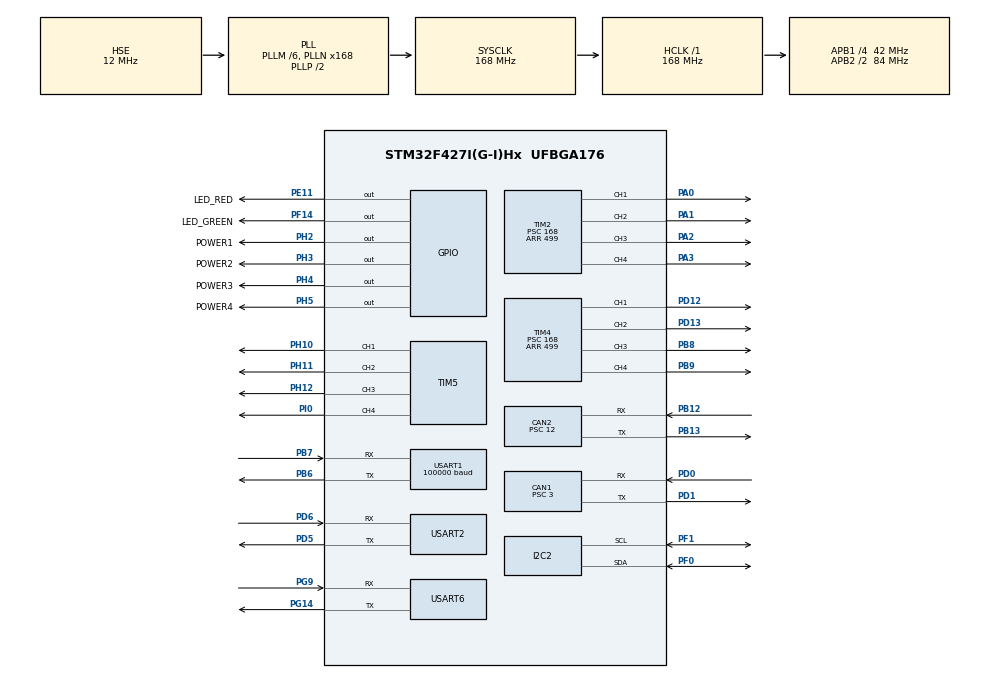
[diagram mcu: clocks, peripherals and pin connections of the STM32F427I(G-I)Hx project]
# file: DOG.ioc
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CAN1.BS1=CAN_BS1_10TQ
CAN1.BS2=CAN_BS2_3TQ
CAN1.CalculateBaudRate=1000000
CAN1.CalculateTimeBit=1000
CAN1.CalculateTimeQuantum=71.42857142857143
CAN1.Prescaler=3
CAN1.TXFP=DISABLE
CAN2.BS1=CAN_BS1_10TQ
CAN2.BS2=CAN_BS2_3TQ
CAN2.CalculateBaudRate=250000
CAN2.CalculateTimeBit=4000
CAN2.CalculateTimeQuantum=285.7142857142857
CAN2.Prescaler=12
CAN2.TXFP=DISABLE
Dma.Request0=USART1_RX
Dma.Request1=USART6_RX
Dma.USART1_RX.0.Direction=DMA_PERIPH_TO_MEMORY
Dma.USART1_RX.0.FIFOMode=DMA_FIFOMODE_DISABLE
Dma.USART1_RX.0.Instance=DMA2_Stream2
Dma.USART1_RX.0.MemDataAlignment=DMA_MDATAALIGN_BYTE
Dma.USART1_RX.0.MemInc=DMA_MINC_ENABLE
Dma.USART1_RX.0.Mode=DMA_CIRCULAR
Dma.USART1_RX.0.PeriphDataAlignment=DMA_PDATAALIGN_BYTE
Dma.USART1_RX.0.PeriphInc=DMA_PINC_DISABLE
Dma.USART1_RX.0.Priority=DMA_PRIORITY_LOW
Dma.USART6_RX.1.Direction=DMA_PERIPH_TO_MEMORY
Dma.USART6_RX.1.FIFOMode=DMA_FIFOMODE_DISABLE
Dma.USART6_RX.1.Instance=DMA2_Stream1
Dma.USART6_RX.1.MemDataAlignment=DMA_MDATAALIGN_BYTE
Dma.USART6_RX.1.MemInc=DMA_MINC_ENABLE
Dma.USART6_RX.1.Mode=DMA_NORMAL
Dma.USART6_RX.1.PeriphDataAlignment=DMA_PDATAALIGN_BYTE
Dma.USART6_RX.1.PeriphInc=DMA_PINC_DISABLE
Dma.USART6_RX.1.Priority=DMA_PRIORITY_LOW
FREERTOS.INCLUDE_eTaskGetState=1
FREERTOS.INCLUDE_pcTaskGetTaskName=1
FREERTOS.INCLUDE_uxTaskGetStackHighWaterMark=1
FREERTOS.INCLUDE_vTaskCleanUpResources=1
FREERTOS.INCLUDE_vTaskDelayUntil=1
FREERTOS.INCLUDE_xEventGroupSetBitFromISR=1
FREERTOS.INCLUDE_xQueueGetMutexHolder=1
FREERTOS.INCLUDE_xSemaphoreGetMutexHolder=1
FREERTOS.INCLUDE_xTaskAbortDelay=1
FREERTOS.INCLUDE_xTaskGetCurrentTaskHandle=1
FREERTOS.INCLUDE_xTaskGetHandle=1
FREERTOS.INCLUDE_xTimerPendFunctionCall=1
FREERTOS.Tasks01=defaultTask,0,128,StartDefaultTask,Default,NULL,Dynamic,NULL,NULL
FREERTOS.configTOTAL_HEAP_SIZE=24576
FREERTOS.configUSE_TIMERS=1
I2C2.I2C_Mode=I2C_Fast
Mcu.Family=STM32F4
Mcu.Name=STM32F427I(G-I)Hx
Mcu.Package=UFBGA176
NVIC.CAN1_RX0_IRQn=true\:5\:0\:false\:false\:true\:true\:true\:true\:true
NVIC.CAN2_RX0_IRQn=true\:5\:0\:false\:false\:true\:true\:true\:true\:true
NVIC.DMA2_Stream1_IRQn=true\:5\:0\:false\:false\:true\:true\:false\:true\:true
NVIC.DMA2_Stream2_IRQn=true\:5\:0\:false\:false\:true\:true\:false\:true\:true
NVIC.PriorityGroup=NVIC_PRIORITYGROUP_4
NVIC.TIM8_TRG_COM_TIM14_IRQn=true\:5\:0\:false\:false\:true\:true\:false\:true\:true
NVIC.TimeBase=TIM8_TRG_COM_TIM14_IRQn
NVIC.TimeBaseIP=TIM14
NVIC.USART1_IRQn=true\:4\:0\:true\:false\:true\:false\:true\:true\:true
NVIC.USART2_IRQn=true\:5\:0\:false\:false\:true\:true\:true\:true\:true
NVIC.USART6_IRQn=true\:5\:0\:false\:false\:true\:true\:true\:true\:true
PA0/WKUP.Signal=S_TIM2_CH1_ETR
PA1.Signal=S_TIM2_CH2
PA13.Mode=Serial_Wire
PA13.Signal=SYS_JTMS-SWDIO
PA14.Mode=Serial_Wire
PA14.Signal=SYS_JTCK-SWCLK
PA2.Signal=S_TIM2_CH3
PA3.Signal=S_TIM2_CH4
PB12.Mode=CAN_Activate
PB12.Signal=CAN2_RX
PB13.Mode=CAN_Activate
PB13.Signal=CAN2_TX
PB6.Mode=Asynchronous
PB6.Signal=USART1_TX
PB7.Mode=Asynchronous
PB7.Signal=USART1_RX
PB8.Signal=S_TIM4_CH3
PB9.Signal=S_TIM4_CH4
PD0.Mode=CAN_Activate
PD0.Signal=CAN1_RX
PD1.Mode=CAN_Activate
PD1.Signal=CAN1_TX
PD12.Signal=S_TIM4_CH1
PD13.Signal=S_TIM4_CH2
PD5.Mode=Asynchronous
PD5.Signal=USART2_TX
PD6.Mode=Asynchronous
PD6.Signal=USART2_RX
PD8.Signal=USART3_TX
PD9.Signal=USART3_RX
PE11.GPIO_Label=LED_RED
PE11.Signal=GPIO_Output
PF0.Mode=I2C
PF0.Signal=I2C2_SDA
PF1.Mode=I2C
PF1.Signal=I2C2_SCL
PF14.GPIO_Label=LED_GREEN
PF14.Signal=GPIO_Output
PG14.Mode=Asynchronous
PG14.Signal=USART6_TX
PG9.Mode=Asynchronous
PG9.Signal=USART6_RX
PH0/OSC_IN.Mode=HSE-External-Oscillator
PH0/OSC_IN.Signal=RCC_OSC_IN
PH1/OSC_OUT.Mode=HSE-External-Oscillator
PH1/OSC_OUT.Signal=RCC_OSC_OUT
PH10.Signal=S_TIM5_CH1
PH11.Signal=S_TIM5_CH2
PH12.Signal=S_TIM5_CH3
PH2.GPIO_Label=POWER1
PH2.GPIO_Speed=GPIO_SPEED_FREQ_VERY_HIGH
PH2.Signal=GPIO_Output
PH3.GPIO_Label=POWER2
PH3.GPIO_Speed=GPIO_SPEED_FREQ_VERY_HIGH
PH3.Signal=GPIO_Output
PH4.GPIO_Label=POWER3
PH4.GPIO_Speed=GPIO_SPEED_FREQ_VERY_HIGH
PH4.Signal=GPIO_Output
PH5.GPIO_Label=POWER4
PH5.GPIO_Speed=GPIO_SPEED_FREQ_VERY_HIGH
PH5.Signal=GPIO_Output
PI0.Signal=S_TIM5_CH4
PI5.Signal=S_TIM8_CH1
ProjectManager.HeapSize=0x200
ProjectManager.StackSize=0x400
ProjectManager.TargetToolchain=MDK-ARM V5
RCC.48MHZClocksFreq_Value=84000000
RCC.AHBFreq_Value=168000000
RCC.APB1CLKDivider=RCC_HCLK_DIV4
RCC.APB1Freq_Value=42000000
RCC.APB1TimFreq_Value=84000000
RCC.APB2CLKDivider=RCC_HCLK_DIV2
RCC.APB2Freq_Value=84000000
RCC.APB2TimFreq_Value=168000000
RCC.CortexFreq_Value=168000000
RCC.HCLKFreq_Value=168000000
RCC.HSE_VALUE=12000000
RCC.HSI_VALUE=16000000
RCC.LSE_VALUE=32768
RCC.PLLM=6
RCC.PLLN=168
RCC.PLLSourceVirtual=RCC_PLLSOURCE_HSE
RCC.SYSCLKFreq_VALUE=168000000
RCC.SYSCLKSource=RCC_SYSCLKSOURCE_PLLCLK
RCC.VCOOutputFreq_Value=336000000
SH.S_TIM2_CH1_ETR.0=TIM2_CH1,PWM Generation1 CH1
SH.S_TIM2_CH2.0=TIM2_CH2,PWM Generation2 CH2
SH.S_TIM2_CH3.0=TIM2_CH3,PWM Generation3 CH3
SH.S_TIM2_CH4.0=TIM2_CH4,PWM Generation4 CH4
SH.S_TIM4_CH1.0=TIM4_CH1,PWM Generation1 CH1
SH.S_TIM4_CH2.0=TIM4_CH2,PWM Generation2 CH2
SH.S_TIM4_CH3.0=TIM4_CH3,PWM Generation3 CH3
SH.S_TIM4_CH4.0=TIM4_CH4,PWM Generation4 CH4
SH.S_TIM5_CH1.0=TIM5_CH1,PWM Generation1 CH1
SH.S_TIM5_CH2.0=TIM5_CH2,PWM Generation2 CH2
SH.S_TIM5_CH3.0=TIM5_CH3,PWM Generation3 CH3
SH.S_TIM5_CH4.0=TIM5_CH4,PWM Generation4 CH4
SH.S_TIM8_CH1.0=TIM8_CH1
TIM2.Channel-PWM\ Generation1\ CH1=TIM_CHANNEL_1
TIM2.Channel-PWM\ Generation2\ CH2=TIM_CHANNEL_2
TIM2.Channel-PWM\ Generation3\ CH3=TIM_CHANNEL_3
TIM2.Channel-PWM\ Generation4\ CH4=TIM_CHANNEL_4
TIM2.OCMode_PWM-PWM\ Generation2\ CH2=TIM_OCMODE_PWM1
TIM2.OCMode_PWM-PWM\ Generation3\ CH3=TIM_OCMODE_PWM2
TIM2.Period=499
TIM2.Prescaler=168
TIM4.Channel-PWM\ Generation1\ CH1=TIM_CHANNEL_1
TIM4.Channel-PWM\ Generation2\ CH2=TIM_CHANNEL_2
TIM4.Channel-PWM\ Generation3\ CH3=TIM_CHANNEL_3
TIM4.Channel-PWM\ Generation4\ CH4=TIM_CHANNEL_4
TIM4.Period=499
TIM4.Prescaler=168
TIM5.Channel-PWM\ Generation1\ CH1=TIM_CHANNEL_1
TIM5.Channel-PWM\ Generation2\ CH2=TIM_CHANNEL_2
TIM5.Channel-PWM\ Generation3\ CH3=TIM_CHANNEL_3
TIM5.Channel-PWM\ Generation4\ CH4=TIM_CHANNEL_4
USART1.BaudRate=100000
USART1.Parity=PARITY_EVEN
USART1.VirtualMode=VM_ASYNC
USART2.VirtualMode=VM_ASYNC
USART6.VirtualMode=VM_ASYNC
VP_FREERTOS_VS_CMSIS_V1.Mode=CMSIS_V1
VP_SYS_VS_tim14.Mode=TIM14
board=RemoteControl

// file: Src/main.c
//test by cuichenyao
/* USER CODE BEGIN Header */
/**
  ******************************************************************************
  * @file           : main.c
  * @brief          : Main program body
  ******************************************************************************
  * @attention
  *
  * Copyright (c) 2022 STMicroelectronics.
  * All rights reserved.
  *
  * This software is licensed under terms that can be found in the LICENSE file
  * in the root directory of this software component.
  * If no LICENSE file comes with this software, it is provided AS-IS.
  *
  ******************************************************************************
  */
/* USER CODE END Header */
#include "main.h"
#include "cmsis_os.h"
#include "can.h"
#include "dma.h"
#include "i2c.h"
#include "tim.h"
#include "usart.h"
#include "gpio.h"

/* USER CODE BEGIN Includes */
#include "bsp_rc.h"
#include "bsp_can.h"
/* USER CODE END Includes */

void SystemClock_Config(void);
void MX_FREERTOS_Init(void);

int main(void)
{

  /* MCU Configuration--------------------------------------------------------*/

  /* Reset of all peripherals, Initializes the Flash interface and the Systick. */
  HAL_Init();

  /* Configure the system clock */
  SystemClock_Config();

  /* Initialize all configured peripherals */
  MX_GPIO_Init();
  MX_DMA_Init();
  MX_USART1_UART_Init();
  MX_CAN1_Init();
  MX_CAN2_Init();
  MX_TIM2_Init();
  MX_TIM4_Init();
  MX_TIM5_Init();
  MX_USART2_UART_Init();
  MX_USART6_UART_Init();
  MX_I2C2_Init();
  /* USER CODE BEGIN 2 */
	dbus_uart_init();
	CAN_Filter_Init();
//  __HAL_UART_ENABLE_IT(&huart6, UART_IT_IDLE);
//  HAL_UART_Receive_DMA(&huart6,&rec,1);
  /* USER CODE END 2 */

  /* Call init function for freertos objects (in freertos.c) */
  MX_FREERTOS_Init();

  /* Start scheduler */
  osKernelStart();
  /* We should never get here as control is now taken by the scheduler */
  /* Infinite loop */
  while (1)
  {

  }
}

void SystemClock_Config(void)
{
  RCC_OscInitTypeDef RCC_OscInitStruct = {0};
  RCC_ClkInitTypeDef RCC_ClkInitStruct = {0};

  /** Configure the main internal regulator output voltage
  */
  __HAL_RCC_PWR_CLK_ENABLE();
  __HAL_PWR_VOLTAGESCALING_CONFIG(PWR_REGULATOR_VOLTAGE_SCALE1);

  /** Initializes the RCC Oscillators according to the specified parameters
  * in the RCC_OscInitTypeDef structure.
  */
  RCC_OscInitStruct.OscillatorType = RCC_OSCILLATORTYPE_HSE;
  RCC_OscInitStruct.HSEState = RCC_HSE_ON;
  RCC_OscInitStruct.PLL.PLLState = RCC_PLL_ON;
  RCC_OscInitStruct.PLL.PLLSource = RCC_PLLSOURCE_HSE;
  RCC_OscInitStruct.PLL.PLLM = 6;
  RCC_OscInitStruct.PLL.PLLN = 168;
  RCC_OscInitStruct.PLL.PLLP = RCC_PLLP_DIV2;
  RCC_OscInitStruct.PLL.PLLQ = 4;
  if (HAL_RCC_OscConfig(&RCC_OscInitStruct) != HAL_OK)
  {
    Error_Handler();
  }

  /** Initializes the CPU, AHB and APB buses clocks
  */
  RCC_ClkInitStruct.ClockType = RCC_CLOCKTYPE_HCLK|RCC_CLOCKTYPE_SYSCLK
                              |RCC_CLOCKTYPE_PCLK1|RCC_CLOCKTYPE_PCLK2;
  RCC_ClkInitStruct.SYSCLKSource = RCC_SYSCLKSOURCE_PLLCLK;
  RCC_ClkInitStruct.AHBCLKDivider = RCC_SYSCLK_DIV1;
  RCC_ClkInitStruct.APB1CLKDivider = RCC_HCLK_DIV4;
  RCC_ClkInitStruct.APB2CLKDivider = RCC_HCLK_DIV2;

  if (HAL_RCC_ClockConfig(&RCC_ClkInitStruct, FLASH_LATENCY_5) != HAL_OK)
  {
    Error_Handler();
  }
}

void HAL_TIM_PeriodElapsedCallback(TIM_HandleTypeDef *htim)
{
  if (htim->Instance == TIM14) {
    HAL_IncTick();
  }
}

void Error_Handler(void)
{
  __disable_irq();
  while (1)
  {
  }
}

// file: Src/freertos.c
/* USER CODE BEGIN Header */
/**
  ******************************************************************************
  * File Name          : freertos.c
  * Description        : Code for freertos applications
  ******************************************************************************
  * @attention
  *
  * Copyright (c) 2022 STMicroelectronics.
  * All rights reserved.
  *
  * This software is licensed under terms that can be found in the LICENSE file
  * in the root directory of this software component.
  * If no LICENSE file comes with this software, it is provided AS-IS.
  *
  ******************************************************************************
  */
/* USER CODE END Header */

#include "FreeRTOS.h"
#include "task.h"
#include "main.h"
#include "cmsis_os.h"

/* USER CODE BEGIN Includes */
#include "detect_task.h"
#include "motor_ctrl.h"
/* USER CODE END Includes */

/* USER CODE BEGIN PTD */
osThreadId chassisTaskHandle;
osThreadId r2TaskHandle;
osThreadId detect_handle;
/* USER CODE END PTD */

osThreadId defaultTaskHandle;

void StartDefaultTask(void const * argument);

void MX_FREERTOS_Init(void); /* (MISRA C 2004 rule 8.1) */

/* GetIdleTaskMemory prototype (linked to static allocation support) */
void vApplicationGetIdleTaskMemory( StaticTask_t **ppxIdleTaskTCBBuffer, StackType_t **ppxIdleTaskStackBuffer, uint32_t *pulIdleTaskStackSize );

/* GetTimerTaskMemory prototype (linked to static allocation support) */
void vApplicationGetTimerTaskMemory( StaticTask_t **ppxTimerTaskTCBBuffer, StackType_t **ppxTimerTaskStackBuffer, uint32_t *pulTimerTaskStackSize );

/* USER CODE BEGIN GET_IDLE_TASK_MEMORY */
static StaticTask_t xIdleTaskTCBBuffer;
static StackType_t xIdleStack[configMINIMAL_STACK_SIZE];

void vApplicationGetIdleTaskMemory( StaticTask_t **ppxIdleTaskTCBBuffer, StackType_t **ppxIdleTaskStackBuffer, uint32_t *pulIdleTaskStackSize )
{
  *ppxIdleTaskTCBBuffer = &xIdleTaskTCBBuffer;
  *ppxIdleTaskStackBuffer = &xIdleStack[0];
  *pulIdleTaskStackSize = configMINIMAL_STACK_SIZE;
  /* place for user code */
}
/* USER CODE END GET_IDLE_TASK_MEMORY */

/* USER CODE BEGIN GET_TIMER_TASK_MEMORY */
static StaticTask_t xTimerTaskTCBBuffer;
static StackType_t xTimerStack[configTIMER_TASK_STACK_DEPTH];

void vApplicationGetTimerTaskMemory( StaticTask_t **ppxTimerTaskTCBBuffer, StackType_t **ppxTimerTaskStackBuffer, uint32_t *pulTimerTaskStackSize )
{
  *ppxTimerTaskTCBBuffer = &xTimerTaskTCBBuffer;
  *ppxTimerTaskStackBuffer = &xTimerStack[0];
  *pulTimerTaskStackSize = configTIMER_TASK_STACK_DEPTH;
  /* place for user code */
}
/* USER CODE END GET_TIMER_TASK_MEMORY */

void MX_FREERTOS_Init(void) {

  /* Create the thread(s) */
  /* definition and creation of defaultTask */
  osThreadDef(defaultTask, StartDefaultTask, osPriorityNormal, 0, 128);
  defaultTaskHandle = osThreadCreate(osThread(defaultTask), NULL);

  /* USER CODE BEGIN RTOS_THREADS */
  /* add threads, ... */
	osThreadDef(ChassisTask, chassis_task, osPriorityAboveNormal, 0, 512);
  chassisTaskHandle = osThreadCreate(osThread(ChassisTask), NULL);

	osThreadDef(DETECT, detect_task, osPriorityNormal, 0, 256);
  detect_handle = osThreadCreate(osThread(DETECT), NULL);
  /* USER CODE END RTOS_THREADS */

}

void StartDefaultTask(void const * argument)
{
  for(;;)
  {
    osDelay(1);
  }
}
